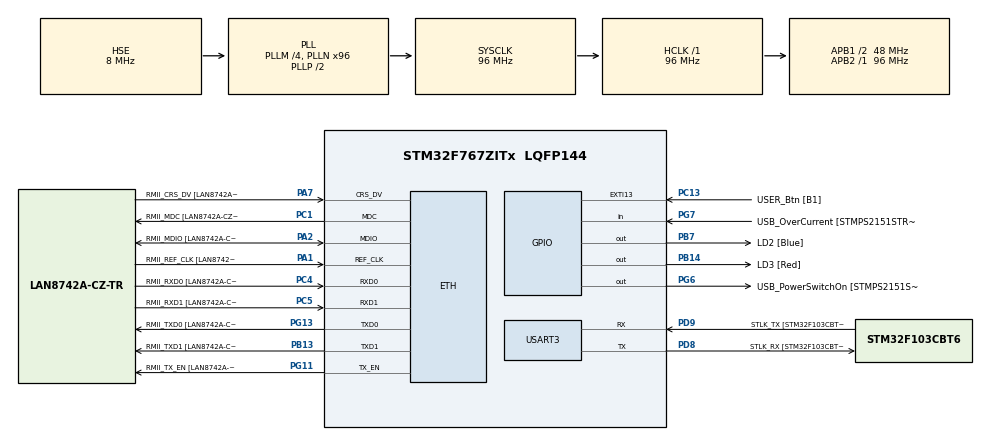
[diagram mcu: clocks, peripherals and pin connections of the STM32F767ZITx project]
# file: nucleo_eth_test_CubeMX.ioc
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ETH.MediaInterface=ETH_MEDIA_INTERFACE_RMII
ETH.PHY_Name=LAN8742A_PHY_ADDRESS
ETH.PHY_Value=0
ETH.PhyAddress=0
FREERTOS.Tasks01=defaultTask,0,128,StartDefaultTask,Default,NULL
LWIP.CHECKSUM_BY_HARDWARE=1
LWIP.GATEWAY_ADDRESS=192.168.001.001
LWIP.IP_ADDRESS=192.168.001.004
LWIP.LWIP_DHCP=0
LWIP.NETMASK_ADDRESS=255.255.255.000
LWIP.Version=v2.0.3_Cube
Mcu.Family=STM32F7
Mcu.Name=STM32F767ZITx
Mcu.Package=LQFP144
NVIC.ETH_IRQn=true\:5\:0\:false\:false\:true\:true\:false\:true
NVIC.PriorityGroup=NVIC_PRIORITYGROUP_4
NVIC.TIM1_UP_TIM10_IRQn=true\:0\:0\:false\:false\:true\:false\:false\:true
NVIC.TimeBase=TIM1_UP_TIM10_IRQn
NVIC.TimeBaseIP=TIM1
PA1.GPIO_Label=RMII_REF_CLK [LAN8742A-CZ-TR_REFCLK0]
PA1.Mode=RMII
PA1.Signal=ETH_REF_CLK
PA10.GPIO_Label=USB_ID
PA10.Signal=USB_OTG_FS_ID
PA11.GPIO_Label=USB_DM
PA11.Signal=USB_OTG_FS_DM
PA12.GPIO_Label=USB_DP
PA12.Signal=USB_OTG_FS_DP
PA13.GPIO_Label=TMS
PA13.Mode=Serial_Wire
PA13.Signal=SYS_JTMS-SWDIO
PA14.GPIO_Label=TCK
PA14.Mode=Serial_Wire
PA14.Signal=SYS_JTCK-SWCLK
PA2.GPIO_Label=RMII_MDIO [LAN8742A-CZ-TR_MDIO]
PA2.Mode=RMII
PA2.Signal=ETH_MDIO
PA7.GPIO_Label=RMII_CRS_DV [LAN8742A-CZ-TR_CRS_DV]
PA7.Mode=RMII
PA7.Signal=ETH_CRS_DV
PA8.GPIO_Label=USB_SOF [TP1]
PA8.Signal=USB_OTG_FS_SOF
PA9.GPIO_Label=USB_VBUS
PA9.Signal=USB_OTG_FS_VBUS
PB13.GPIO_Label=RMII_TXD1 [LAN8742A-CZ-TR_TXD1]
PB13.Mode=RMII
PB13.Signal=ETH_TXD1
PB14.GPIO_Label=LD3 [Red]
PB14.Signal=GPIO_Output
PB3.GPIO_Label=SWO
PB3.Signal=SYS_JTDO-SWO
PB7.GPIO_Label=LD2 [Blue]
PB7.Signal=GPIO_Output
PC1.GPIO_Label=RMII_MDC [LAN8742A-CZ-TR_MDC]
PC1.Mode=RMII
PC1.Signal=ETH_MDC
PC13.GPIO_Label=USER_Btn [B1]
PC13.Signal=GPXTI13
PC14/OSC32_IN.Mode=LSE-External-Oscillator
PC14/OSC32_IN.Signal=RCC_OSC32_IN
PC15/OSC32_OUT.Mode=LSE-External-Oscillator
PC15/OSC32_OUT.Signal=RCC_OSC32_OUT
PC4.GPIO_Label=RMII_RXD0 [LAN8742A-CZ-TR_RXD0]
PC4.Mode=RMII
PC4.Signal=ETH_RXD0
PC5.GPIO_Label=RMII_RXD1 [LAN8742A-CZ-TR_RXD1]
PC5.Mode=RMII
PC5.Signal=ETH_RXD1
PD8.GPIO_Label=STLK_RX [STM32F103CBT6_PA3]
PD8.Mode=Asynchronous
PD8.Signal=USART3_TX
PD9.GPIO_Label=STLK_TX [STM32F103CBT6_PA2]
PD9.Mode=Asynchronous
PD9.Signal=USART3_RX
PG11.GPIO_Label=RMII_TX_EN [LAN8742A-CZ-TR_TXEN]
PG11.Mode=RMII
PG11.Signal=ETH_TX_EN
PG13.GPIO_Label=RMII_TXD0 [LAN8742A-CZ-TR_TXD0]
PG13.Mode=RMII
PG13.Signal=ETH_TXD0
PG6.GPIO_Label=USB_PowerSwitchOn [STMPS2151STR_EN]
PG6.Signal=GPIO_Output
PG7.GPIO_Label=USB_OverCurrent [STMPS2151STR_FAULT]
PG7.Signal=GPIO_Input
PH0/OSC_IN.GPIO_Label=MCO [STM32F103CBT6_PA8]
PH0/OSC_IN.Mode=HSE-External-Clock-Source
PH0/OSC_IN.Signal=RCC_OSC_IN
PH1/OSC_OUT.Mode=HSE-External-Clock-Source
PH1/OSC_OUT.Signal=RCC_OSC_OUT
ProjectManager.HeapSize=0x200
ProjectManager.StackSize=0x400
ProjectManager.TargetToolchain=SW4STM32
RCC.48MHZClocksFreq_Value=24000000
RCC.AHBFreq_Value=96000000
RCC.APB1CLKDivider=RCC_HCLK_DIV2
RCC.APB1Freq_Value=48000000
RCC.APB1TimFreq_Value=96000000
RCC.APB2Freq_Value=96000000
RCC.APB2TimFreq_Value=96000000
RCC.CortexFreq_Value=96000000
RCC.HCLKFreq_Value=96000000
RCC.HSE_VALUE=8000000
RCC.HSI_VALUE=16000000
RCC.PLLM=4
RCC.PLLMUL=RCC_PLL_MUL9
RCC.PLLN=96
RCC.PLLQ=4
RCC.PLLSourceVirtual=RCC_PLLSOURCE_HSE
RCC.PRESCALERUSB=RCC_USBCLKSOURCE_PLL_DIV1_5
RCC.SYSCLKFreq_VALUE=96000000
RCC.SYSCLKSource=RCC_SYSCLKSOURCE_PLLCLK
RCC.SYSCLKSourceVirtual=RCC_SYSCLKSOURCE_PLLCLK
RCC.USBFreq_Value=48000000
RCC.VCOOutputFreq_Value=192000000
USART3.VirtualMode-Asynchronous=VM_ASYNC
VP_FREERTOS_VS_CMSIS_V1.Mode=CMSIS_V1
VP_LWIP_VS_Enabled.Mode=Enabled
VP_SYS_VS_tim1.Mode=TIM1
board=NUCLEO-F767ZI

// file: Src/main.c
/* USER CODE BEGIN Header */
/**
  ******************************************************************************
  * @file           : main.c
  * @brief          : Main program body
  ******************************************************************************
  * @attention
  *
  * <h2><center>&copy; Copyright (c) 2019 STMicroelectronics.
  * All rights reserved.</center></h2>
  *
  * This software component is licensed by ST under Ultimate Liberty license
  * SLA0044, the "License"; You may not use this file except in compliance with
  * the License. You may obtain a copy of the License at:
  *                             www.st.com/SLA0044
  *
  ******************************************************************************
  */
/* USER CODE END Header */

#include "main.h"
#include "cmsis_os.h"
#include "lwip.h"
#include "sockets.h"
#include "lwip/api.h"
#include "string.h"
#include <stdio.h>
#include "lwip/udp.h"
#include <time.h>

/* USER CODE BEGIN PD */
#define UDPCLIENT_THREAD_PRIO    ( osPriorityAboveNormal )
/* USER CODE END PD */

/* USER CODE BEGIN PM */
#define PT_PROTOCOL_VERSION 0xa74aa8ef
/* USER CODE END PM */

size_t               m_read_data = 0;

UART_HandleTypeDef huart3;

osThreadId defaultTaskHandle;

struct py_base_packet{
	uint8_t  state;
	uint32_t pairedIP;   // TODO: Introduce proper IPADdress type
	uint8_t  hasStaticConfig;
	uint8_t  hasHandover;
	uint8_t  hasIFace;
	uint8_t  version_macer[30];
	uint8_t  version_driver[30];
	uint8_t  version_fwinc[30];
	uint8_t  version_fwplat[30];
	uint8_t  version_fwmac[30];
	uint8_t  version_client[30];
	uint8_t  error_msg[50];
};

void SystemClock_Config(void);
static void MX_GPIO_Init(void);
static void MX_USART3_UART_Init(void);
void StartDefaultTask(void const * argument);

int main(void)
{

  /* MCU Configuration--------------------------------------------------------*/

  /* Reset of all peripherals, Initializes the Flash interface and the Systick. */
  HAL_Init();

  /* Configure the system clock */
  SystemClock_Config();

  /* Initialize all configured peripherals */
  MX_GPIO_Init();
  MX_USART3_UART_Init();

  /* Create the thread(s) */
  /* definition and creation of defaultTask */
  osThreadDef(defaultTask, StartDefaultTask, osPriorityNormal, 0, 128);
  defaultTaskHandle = osThreadCreate(osThread(defaultTask), NULL);

  /* Start scheduler */
  osKernelStart();

  /* We should never get here as control is now taken by the scheduler */

  /* Infinite loop */
  while (1)
  {

  }
}

void SystemClock_Config(void)
{
  RCC_OscInitTypeDef RCC_OscInitStruct = {0};
  RCC_ClkInitTypeDef RCC_ClkInitStruct = {0};
  RCC_PeriphCLKInitTypeDef PeriphClkInitStruct = {0};

  /** Configure LSE Drive Capability
  */
  HAL_PWR_EnableBkUpAccess();
  /** Configure the main internal regulator output voltage
  */
  __HAL_RCC_PWR_CLK_ENABLE();
  __HAL_PWR_VOLTAGESCALING_CONFIG(PWR_REGULATOR_VOLTAGE_SCALE3);
  /** Initializes the CPU, AHB and APB busses clocks
  */
  RCC_OscInitStruct.OscillatorType = RCC_OSCILLATORTYPE_HSE;
  RCC_OscInitStruct.HSEState = RCC_HSE_BYPASS;
  RCC_OscInitStruct.PLL.PLLState = RCC_PLL_ON;
  RCC_OscInitStruct.PLL.PLLSource = RCC_PLLSOURCE_HSE;
  RCC_OscInitStruct.PLL.PLLM = 4;
  RCC_OscInitStruct.PLL.PLLN = 96;
  RCC_OscInitStruct.PLL.PLLP = RCC_PLLP_DIV2;
  RCC_OscInitStruct.PLL.PLLQ = 4;
  if (HAL_RCC_OscConfig(&RCC_OscInitStruct) != HAL_OK)
  {
    Error_Handler();
  }
  /** Activate the Over-Drive mode
  */
  if (HAL_PWREx_EnableOverDrive() != HAL_OK)
  {
    Error_Handler();
  }
  /** Initializes the CPU, AHB and APB busses clocks
  */
  RCC_ClkInitStruct.ClockType = RCC_CLOCKTYPE_HCLK|RCC_CLOCKTYPE_SYSCLK
                              |RCC_CLOCKTYPE_PCLK1|RCC_CLOCKTYPE_PCLK2;
  RCC_ClkInitStruct.SYSCLKSource = RCC_SYSCLKSOURCE_PLLCLK;
  RCC_ClkInitStruct.AHBCLKDivider = RCC_SYSCLK_DIV1;
  RCC_ClkInitStruct.APB1CLKDivider = RCC_HCLK_DIV2;
  RCC_ClkInitStruct.APB2CLKDivider = RCC_HCLK_DIV1;

  if (HAL_RCC_ClockConfig(&RCC_ClkInitStruct, FLASH_LATENCY_3) != HAL_OK)
  {
    Error_Handler();
  }
  PeriphClkInitStruct.PeriphClockSelection = RCC_PERIPHCLK_USART3;
  PeriphClkInitStruct.Usart3ClockSelection = RCC_USART3CLKSOURCE_PCLK1;
  if (HAL_RCCEx_PeriphCLKConfig(&PeriphClkInitStruct) != HAL_OK)
  {
    Error_Handler();
  }
}

static void MX_USART3_UART_Init(void)
{

  huart3.Instance = USART3;
  huart3.Init.BaudRate = 115200;
  huart3.Init.WordLength = UART_WORDLENGTH_8B;
  huart3.Init.StopBits = UART_STOPBITS_1;
  huart3.Init.Parity = UART_PARITY_NONE;
  huart3.Init.Mode = UART_MODE_TX_RX;
  huart3.Init.HwFlowCtl = UART_HWCONTROL_NONE;
  huart3.Init.OverSampling = UART_OVERSAMPLING_16;
  huart3.Init.OneBitSampling = UART_ONE_BIT_SAMPLE_DISABLE;
  huart3.AdvancedInit.AdvFeatureInit = UART_ADVFEATURE_NO_INIT;
  if (HAL_UART_Init(&huart3) != HAL_OK)
  {
    Error_Handler();
  }

}

static void MX_GPIO_Init(void)
{
  GPIO_InitTypeDef GPIO_InitStruct = {0};

  /* GPIO Ports Clock Enable */
  __HAL_RCC_GPIOC_CLK_ENABLE();
  __HAL_RCC_GPIOH_CLK_ENABLE();
  __HAL_RCC_GPIOA_CLK_ENABLE();
  __HAL_RCC_GPIOB_CLK_ENABLE();
  __HAL_RCC_GPIOD_CLK_ENABLE();
  __HAL_RCC_GPIOG_CLK_ENABLE();

  /*Configure GPIO pin Output Level */
  HAL_GPIO_WritePin(GPIOB, LD3_Pin|LD2_Pin, GPIO_PIN_RESET);

  /*Configure GPIO pin Output Level */
  HAL_GPIO_WritePin(USB_PowerSwitchOn_GPIO_Port, USB_PowerSwitchOn_Pin, GPIO_PIN_RESET);

  /*Configure GPIO pin : USER_Btn_Pin */
  GPIO_InitStruct.Pin = USER_Btn_Pin;
  GPIO_InitStruct.Mode = GPIO_MODE_IT_RISING;
  GPIO_InitStruct.Pull = GPIO_NOPULL;
  HAL_GPIO_Init(USER_Btn_GPIO_Port, &GPIO_InitStruct);

  /*Configure GPIO pins : LD3_Pin LD2_Pin */
  GPIO_InitStruct.Pin = LD3_Pin|LD2_Pin;
  GPIO_InitStruct.Mode = GPIO_MODE_OUTPUT_PP;
  GPIO_InitStruct.Pull = GPIO_NOPULL;
  GPIO_InitStruct.Speed = GPIO_SPEED_FREQ_LOW;
  HAL_GPIO_Init(GPIOB, &GPIO_InitStruct);

  /*Configure GPIO pin : USB_PowerSwitchOn_Pin */
  GPIO_InitStruct.Pin = USB_PowerSwitchOn_Pin;
  GPIO_InitStruct.Mode = GPIO_MODE_OUTPUT_PP;
  GPIO_InitStruct.Pull = GPIO_NOPULL;
  GPIO_InitStruct.Speed = GPIO_SPEED_FREQ_LOW;
  HAL_GPIO_Init(USB_PowerSwitchOn_GPIO_Port, &GPIO_InitStruct);

  /*Configure GPIO pin : USB_OverCurrent_Pin */
  GPIO_InitStruct.Pin = USB_OverCurrent_Pin;
  GPIO_InitStruct.Mode = GPIO_MODE_INPUT;
  GPIO_InitStruct.Pull = GPIO_NOPULL;
  HAL_GPIO_Init(USB_OverCurrent_GPIO_Port, &GPIO_InitStruct);

  /*Configure GPIO pins : USB_SOF_Pin USB_ID_Pin USB_DM_Pin USB_DP_Pin */
  GPIO_InitStruct.Pin = USB_SOF_Pin|USB_ID_Pin|USB_DM_Pin|USB_DP_Pin;
  GPIO_InitStruct.Mode = GPIO_MODE_AF_PP;
  GPIO_InitStruct.Pull = GPIO_NOPULL;
  GPIO_InitStruct.Speed = GPIO_SPEED_FREQ_VERY_HIGH;
  GPIO_InitStruct.Alternate = GPIO_AF10_OTG_FS;
  HAL_GPIO_Init(GPIOA, &GPIO_InitStruct);

  /*Configure GPIO pin : USB_VBUS_Pin */
  GPIO_InitStruct.Pin = USB_VBUS_Pin;
  GPIO_InitStruct.Mode = GPIO_MODE_INPUT;
  GPIO_InitStruct.Pull = GPIO_NOPULL;
  HAL_GPIO_Init(USB_VBUS_GPIO_Port, &GPIO_InitStruct);

}

void serialize()
{
	uint32_t vers = PT_PROTOCOL_VERSION;
	uint8_t  type = 3; //PT_NODE_STATE

}

uint8_t readU8(uint8_t *buffer)
{
	uint8_t c = buffer[m_read_data];
	m_read_data++;
	return c;
}

uint32_t readU32(uint8_t *buffer)
{
	return readU8(buffer) + readU8(buffer) * 0x100 + readU8(buffer) * 0x10000 + readU8(buffer) * 0x1000000;

}

void delay(int seconds)
{
	int ms = 1000*seconds;

	clock_t start_time = clock();
	while (clock() < start_time + ms)
	        ;
}

static void udp_client_netconn_thread(void *arg)
{

	int socket_fd;
	struct sockaddr_in sa,ra;

	 const TickType_t xDelay = 1000 ;
	int sent_data; char recv_data_buffer[80];
	/* Creates an UDP socket (SOCK_DGRAM) with Internet Protocol Family (PF_INET).
	 * Protocol family and Address family related. For example PF_INET Protocol Family and AF_INET family are coupled.
	*/
	socket_fd = socket(AF_INET, SOCK_DGRAM, 0);

	if ( socket_fd < 0 )
	{

	    printf("socket call failed");
	    exit(0);

	}

	memset(&sa, 0, sizeof(struct sockaddr_in));
	sa.sin_family = AF_INET;
	sa.sin_addr.s_addr = INADDR_ANY;
	sa.sin_port = htons(17225);

	/* Bind the TCP socket to the port SENDER_PORT_NUM and to the current
	* machines IP address (Its defined by SENDER_IP_ADDR).
	* Once bind is successful for UDP sockets application can operate
	* on the socket descriptor for sending or receiving data.
	*/
	if (bind(socket_fd, (struct sockaddr *)&sa, sizeof(struct sockaddr_in)) == -1)
	{
	printf("Bind to Port Number %d ,IP address %s failed\n",17225,"192.168.1.4");
	close(socket_fd);
	exit(1);
	}

	memset(&ra, 0, sizeof(struct sockaddr_in));
	ra.sin_family = AF_INET;
	ra.sin_addr.s_addr = INADDR_ANY;
	ra.sin_port = htons(17225);

	uint8_t  buffer[256];

	unsigned int addr_size = sizeof(ra);

	while(1)
	{
		int msgLen = recvfrom(socket_fd,buffer,256,0,(struct sockaddr *)&ra,(socklen_t *)&addr_size);

		struct sockaddr_in destaddr = {
							.sin_family = AF_INET,
							.sin_port = ra.sin_port,
							//.sin_addr ={.s_addr = inet_addr("224.3.3.3")},
							.sin_addr   = {.s_addr = ra.sin_addr.s_addr},
							.sin_zero   = {0},
						};

		vTaskDelay(xDelay);
		sent_data = sendto(socket_fd, buffer,sizeof("Hello World"),0,(struct sockaddr*)&destaddr,sizeof(destaddr));
		if(sent_data < 0)
		{

			printf("send failed\n");
			close(socket_fd);
			exit(2);

		}
		vTaskDelay(xDelay);
	}

	close(socket_fd);

}

void udp_client_netconn_init()
{
	sys_thread_new("UDP", udp_client_netconn_thread,NULL,DEFAULT_THREAD_STACKSIZE,UDPCLIENT_THREAD_PRIO);
}

void StartDefaultTask(void const * argument)
{
  /* init code for LWIP */
  MX_LWIP_Init();

  udp_client_netconn_init();
  for(;;)
  {
    osDelay(1);
  }
}

void HAL_TIM_PeriodElapsedCallback(TIM_HandleTypeDef *htim)
{
  if (htim->Instance == TIM1) {
    HAL_IncTick();
  }
}

void Error_Handler(void)
{
}

/************************ (C) COPYRIGHT STMicroelectronics *****END OF FILE****/
